# GD32E501 register map
File version: 1.0
CPU: CM33 r0p4, little endian, MPU, FPU, 4 interrupt priority bits
Registers are 32-bit, read-write, reset 0x0 unless marked. A register's access mark holds for its fields unless they carry their own. Offsets are from the block's base; [hi:lo] are bit positions.

## MDIO — Management data input/output
Base 0x4000D800
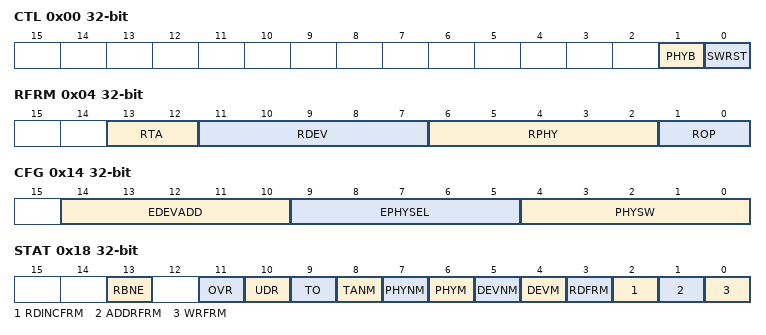
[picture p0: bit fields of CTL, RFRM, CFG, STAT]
0x00 CTL — Control register
  [1] PHYB — MDIO PHY bit length
  [0] SWRST — Software reset
0x04 RFRM — Received frame information register
  [13:12] RTA — Received frame field TA
  [11:7] RDEV — Received frame field DEVADD
  [6:2] RPHY — Received frame field PHYADR
  [1:0] ROP — Received frame field OP
0x08 RDATA read — Received data register
  [15:0] RDATA — Received frame field DATA
0x0C RADDR read — Received address register
  [15:0] RADDR — Received frame field ADDRESS
0x10 TDATA read — Transfer data register
  [15:0] TDATA — Transfer data
0x14 CFG — Configuration register
  [14:10] EDEVADD — Expected DEVADD
  [9:5] EPHYSEL — Selects expected PHYADR
  [4:0] PHYSW — Software provided PHYADR
0x18 STAT read — Status register
  [13] RBNE — Read data buffer not empty flag
  [11] OVR — Receive overrun flag
  [10] UDR — Transmit underrun flag
  [9] TO — Timeout flag
  [8] TANM — Set at end bit of TA of a write data frame or a write address frame
  [7] PHYNM — Set at end bit of PHYADR if PHYADR nonmatches
  [6] PHYM — Set at end bit of PHYADR if PHYADR matches
  [5] DEVNM — Set at end bit of DEVADD if DEVADD nonmatches
  [4] DEVM — Set at end bit of DEVADD if DEVADD matches
  [3] RDFRM — Set at end bit of a read data frame if DEVADD and PHYADR both match
  [2] RDINCFRM — Set at end bit of a post read increment address frame if DEVADD and PHYADR both match
  [1] ADDRFRM — Set at end bit of a write address frame if DEVADD and PHYADR both match
  [0] WRFRM — Set at end bit of a write data frame if DEVADD and PHYADR both match
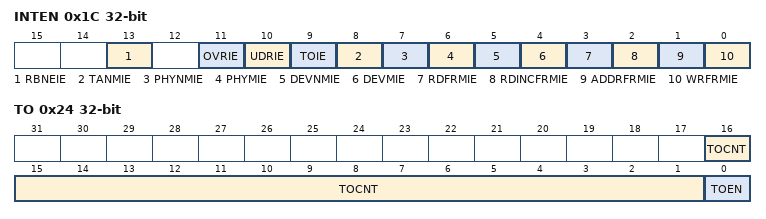
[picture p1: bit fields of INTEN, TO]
0x1C INTEN — Interrupt enable register
  [13] RBNEIE — interrupt is requested when RBDE bit in MDIO_STAT register becomes active
  [11] OVRIE — interrupt is requested when OVR bit in MDIO_STAT register becomes active
  [10] UDRIE — interrupt is requested when UDR bit in MDIO_STAT register becomes active
  [9] TOIE — interrupt is requested when TO bit in MDIO_STAT register becomes active
  [8] TANMIE — interrupt is requested when TANM bit in MDIO_STAT register becomes active
  [7] PHYNMIE — interrupt is requested when PHYNM bit in MDIO_STAT register becomes active
  [6] PHYMIE — interrupt is requested when PHYM bit in MDIO_STAT register becomes active
  [5] DEVNMIE — interrupt is requested when DEVNM bit in MDIO_STAT register becomes active
  [4] DEVMIE — interrupt is requested when DEVM bit in MDIO_STAT register becomes active
  [3] RDFRMIE — interrupt is requested when RDFRM bit in MDIO_STAT register becomes active
  [2] RDINCFRMIE — interrupt is requested when RDINCFRM bit in MDIO_STAT register becomes active
  [1] ADDRFRMIE — interrupt is requested when ADDRFRM bit in MDIO_STAT register becomes active
  [0] WRFRMIE — interrupt is requested when WRFRM bit in MDIO_STAT register becomes active
0x20 PIN read — pin value register
  [4:0] PHYPIN — Pin value read from hardware PRTADR[4:0] pins
0x24 TO read — Timeout register
  [16:1] TOCNT — MDIO time out
  [0] TOEN — Timeout enable

## PMU — Power management unit
Base 0x40007000
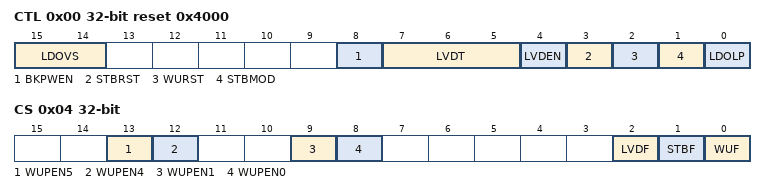
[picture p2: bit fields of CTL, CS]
0x00 CTL reset 0x4000 — power control register
  [15:14] LDOVS — LDO output voltage select
  [8] BKPWEN — Backup Domain Write Enable
  [7:5] LVDT — Low Voltage Detector Threshold
  [4] LVDEN — Low Voltage Detector Enable
  [3] STBRST — Standby Flag Reset
  [2] WURST — Wakeup Flag Reset
  [1] STBMOD — Standby Mode
  [0] LDOLP — LDO Low Power Mode
0x04 CS access per field — power control/status register
  [13] WUPEN5 rw — WKUP pin5 Enable
  [12] WUPEN4 rw — WKUP pin4 Enable
  [9] WUPEN1 rw — WKUP pin1 Enable
  [8] WUPEN0 rw — WKUP pin0 Enable
  [2] LVDF ro — Low Voltage Detector Status Flag
  [1] STBF ro — Standby flag
  [0] WUF ro — Wakeup flag
